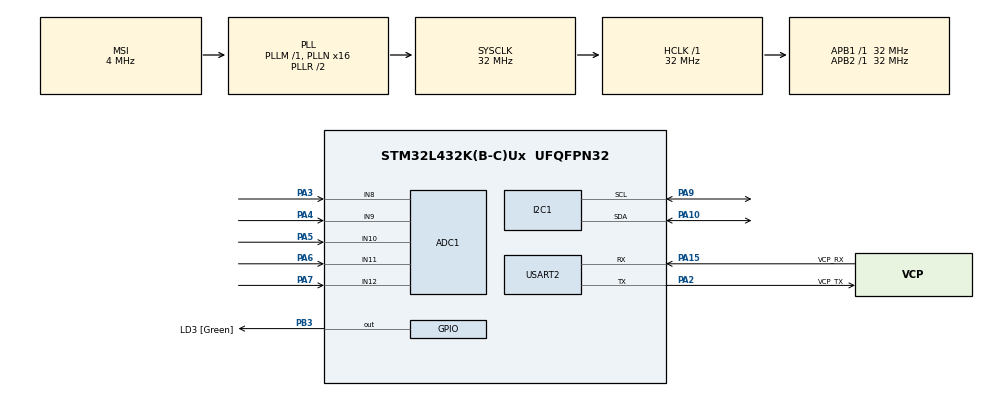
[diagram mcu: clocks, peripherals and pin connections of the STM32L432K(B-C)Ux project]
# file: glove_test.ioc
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ADC1.Channel-0\#ChannelRegularConversion=ADC_CHANNEL_8
ADC1.Channel-1\#ChannelRegularConversion=ADC_CHANNEL_9
ADC1.Channel-2\#ChannelRegularConversion=ADC_CHANNEL_10
ADC1.Channel-3\#ChannelRegularConversion=ADC_CHANNEL_11
ADC1.Channel-4\#ChannelRegularConversion=ADC_CHANNEL_12
ADC1.ClockPrescaler=ADC_CLOCK_SYNC_PCLK_DIV4
ADC1.ContinuousConvMode=ENABLE
ADC1.DMAContinuousRequests=ENABLE
ADC1.NbrOfConversion=5
ADC1.NbrOfConversionFlag=1
ADC1.OffsetNumber-0\#ChannelRegularConversion=ADC_OFFSET_NONE
ADC1.OffsetNumber-1\#ChannelRegularConversion=ADC_OFFSET_NONE
ADC1.OffsetNumber-2\#ChannelRegularConversion=ADC_OFFSET_NONE
ADC1.OffsetNumber-3\#ChannelRegularConversion=ADC_OFFSET_NONE
ADC1.OffsetNumber-4\#ChannelRegularConversion=ADC_OFFSET_NONE
ADC1.Rank-0\#ChannelRegularConversion=1
ADC1.Rank-1\#ChannelRegularConversion=2
ADC1.Rank-2\#ChannelRegularConversion=3
ADC1.Rank-3\#ChannelRegularConversion=4
ADC1.Rank-4\#ChannelRegularConversion=5
ADC1.SamplingTime-0\#ChannelRegularConversion=ADC_SAMPLETIME_2CYCLES_5
ADC1.SamplingTime-1\#ChannelRegularConversion=ADC_SAMPLETIME_2CYCLES_5
ADC1.SamplingTime-2\#ChannelRegularConversion=ADC_SAMPLETIME_2CYCLES_5
ADC1.SamplingTime-3\#ChannelRegularConversion=ADC_SAMPLETIME_2CYCLES_5
ADC1.SamplingTime-4\#ChannelRegularConversion=ADC_SAMPLETIME_2CYCLES_5
ADC1.master=1
Dma.ADC1.0.Direction=DMA_PERIPH_TO_MEMORY
Dma.ADC1.0.Instance=DMA1_Channel1
Dma.ADC1.0.MemDataAlignment=DMA_MDATAALIGN_HALFWORD
Dma.ADC1.0.MemInc=DMA_MINC_ENABLE
Dma.ADC1.0.Mode=DMA_CIRCULAR
Dma.ADC1.0.PeriphDataAlignment=DMA_PDATAALIGN_HALFWORD
Dma.ADC1.0.PeriphInc=DMA_PINC_DISABLE
Dma.ADC1.0.Priority=DMA_PRIORITY_LOW
Dma.Request0=ADC1
I2C1.Timing=0x00707CBB
Mcu.Family=STM32L4
Mcu.Name=STM32L432K(B-C)Ux
Mcu.Package=UFQFPN32
NVIC.DMA1_Channel1_IRQn=true\:0\:0\:false\:false\:true\:false\:true
NVIC.PriorityGroup=NVIC_PRIORITYGROUP_4
PA0.GPIO_Label=MCO [High speed clock in]
PA0.Mode=HSE-External-Clock-Source-for-LittleOrca
PA0.Signal=RCC_CK_IN
PA10.Mode=I2C
PA10.Signal=I2C1_SDA
PA13\ (JTMS-SWDIO).GPIO_Label=SWDIO
PA13\ (JTMS-SWDIO).Mode=Serial_Wire
PA13\ (JTMS-SWDIO).Signal=SYS_JTMS-SWDIO
PA14\ (JTCK-SWCLK).GPIO_Label=SWCLK
PA14\ (JTCK-SWCLK).Mode=Serial_Wire
PA14\ (JTCK-SWCLK).Signal=SYS_JTCK-SWCLK
PA15\ (JTDI).GPIO_Label=VCP_RX
PA15\ (JTDI).Mode=Asynchronous
PA15\ (JTDI).Signal=USART2_RX
PA2.GPIO_Label=VCP_TX
PA2.Mode=Asynchronous
PA2.Signal=USART2_TX
PA3.Signal=ADCx_IN8
PA4.Signal=ADCx_IN9
PA5.Signal=ADCx_IN10
PA6.Signal=ADCx_IN11
PA7.Signal=ADCx_IN12
PA9.Mode=I2C
PA9.Signal=I2C1_SCL
PB3\ (JTDO-TRACESWO).GPIO_Label=LD3 [Green]
PB3\ (JTDO-TRACESWO).Signal=GPIO_Output
PC14-OSC32_IN\ (PC14).Mode=LSE-External-Oscillator
PC14-OSC32_IN\ (PC14).Signal=RCC_OSC32_IN
PC15-OSC32_OUT\ (PC15).Mode=LSE-External-Oscillator
PC15-OSC32_OUT\ (PC15).Signal=RCC_OSC32_OUT
ProjectManager.HeapSize=0x200
ProjectManager.StackSize=0x400
ProjectManager.TargetToolchain=TrueSTUDIO
RCC.ADCFreq_Value=32000000
RCC.AHBFreq_Value=32000000
RCC.APB1Freq_Value=32000000
RCC.APB1TimFreq_Value=32000000
RCC.APB2Freq_Value=32000000
RCC.APB2TimFreq_Value=32000000
RCC.CortexFreq_Value=32000000
RCC.HCLKFreq_Value=32000000
RCC.HSE_VALUE=8000000
RCC.HSI16_VALUE=16000000
RCC.HSI48_VALUE=48000000
RCC.HSI_VALUE=16000000
RCC.MSI_VALUE=4000000
RCC.PLLMUL=RCC_PLLMUL_4
RCC.PLLN=16
RCC.PLLSAI1N=16
RCC.SYSCLKFreq_VALUE=32000000
RCC.SYSCLKSource=RCC_SYSCLKSOURCE_PLLCLK
RCC.USBFreq_Value=32000000
RCC.VCOOutputFreq_Value=64000000
SH.ADCx_IN10.0=ADC1_IN10,IN10-Single-Ended
SH.ADCx_IN11.0=ADC1_IN11,IN11-Single-Ended
SH.ADCx_IN12.0=ADC1_IN12,IN12-Single-Ended
SH.ADCx_IN8.0=ADC1_IN8,IN8-Single-Ended
SH.ADCx_IN9.0=ADC1_IN9,IN9-Single-Ended
USART2.VirtualMode-Asynchronous=VM_ASYNC
board=NUCLEO-L432KC

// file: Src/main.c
#include "main.h"
#include <stdio.h>
#include <string.h>

ADC_HandleTypeDef hadc1;
DMA_HandleTypeDef hdma_adc1;
I2C_HandleTypeDef hi2c1;
UART_HandleTypeDef huart2;

/* USER CODE BEGIN PV */
uint16_t adcBuffer[5];
uint16_t angle[5];
char adc_value[20] = { 0 };

/* USER CODE END PV */

void SystemClock_Config(void);
static void MX_GPIO_Init(void);
static void MX_DMA_Init(void);
static void MX_ADC1_Init(void);
static void MX_USART2_UART_Init(void);
static void MX_I2C1_Init(void);

void ScreenSend(uint8_t * pData) {
	int length = strlen((char*) pData);	//Calculate string length
	HAL_I2C_Master_Transmit(&hi2c1, 0x72 << 1, pData, length, 10);//Address 0x72
}

long map(long x, long in_min, long in_max, long out_min, long out_max) {
	return (x - in_min) * (out_max - out_min) / (in_max - in_min) + out_min;
}

void thumbFinger(uint16_t angle);
void indexFinger(uint16_t angle);
void middleFinger(uint16_t angle);
void ringFinger(uint16_t angle);
void littleFinger(uint16_t angle);

void thumbFinger(uint16_t angle) {
	if (angle >= 30 && angle <= 40) {
		printf("Finger Bend at 35.\r\n");
		ScreenSend((uint8_t *) "|-I need water");
	}

	else if (angle >= 85 && angle <= 95) {
		printf("Finger Bend at 90.\r\n");
		ScreenSend((uint8_t *) "|-I need food");
	}

	else if (angle >= 105 && angle <= 115) {
		printf("Finger Bend at 120.\r\n");
		ScreenSend((uint8_t *) "|-I need medicine");
	}
	HAL_Delay(100);
}

void indexFinger(uint16_t angle) {
	if (angle >= 30 && angle <= 40) {
		printf("Finger Bend at 35.\r\n");
		ScreenSend((uint8_t *) "|-Hello, I'm Aman!");
	}

	else if (angle >= 85 && angle <= 95) {
		printf("Finger Bend at 90.\r\n");
		ScreenSend((uint8_t *) "|-I'm good");
	}

	else if (angle >= 105 && angle <= 115) {
		printf("Finger Bend at 120.\r\n");
		ScreenSend((uint8_t *) "|-How are you?");
	}
	HAL_Delay(100);
}

void middleFinger(uint16_t angle) {
	if (angle >= 30 && angle <= 40) {
		printf("Finger Bend at 35.\r\n");
		ScreenSend((uint8_t *) "|-I need wheelchair");
	}

	else if (angle >= 85 && angle <= 95) {
		printf("Finger Bend at 90.\r\n");
		ScreenSend((uint8_t *) "|-I'm tired");
	}

	else if (angle >= 105 && angle <= 115) {
		printf("Finger Bend at 120.\r\n");
		ScreenSend((uint8_t *) "|-I'm sleepy");
	}
	HAL_Delay(100);
}

void ringFinger(uint16_t angle) {
	if (angle >= 30 && angle <= 40) {
		printf("Finger Bend at 35.\r\n");
		ScreenSend((uint8_t *) "|-Where's my phone?");
	}

	else if (angle >= 85 && angle <= 95) {
		printf("Finger Bend at 90.\r\n");
		ScreenSend((uint8_t *) "|-Call on this number.");
	}

	else if (angle >= 105 && angle <= 115) {
		printf("Finger Bend at 120.\r\n");
		ScreenSend((uint8_t *) "|-Tell my address.");
	}
	HAL_Delay(100);
}

void littleFinger(uint16_t angle) {
	if (angle >= 30 && angle <= 40) {
		printf("Finger Bend at 35.\r\n");
		ScreenSend((uint8_t *) "|-Thank you!");
	}

	else if (angle >= 85 && angle <= 95) {
		printf("Finger Bend at 90.\r\n");
		ScreenSend((uint8_t *) "|-Nice to meet you.");
	}

	else if (angle >= 105 && angle <= 115) {
		printf("Finger Bend at 120.\r\n");
		ScreenSend((uint8_t *) "|-Goodbye");
	}
	HAL_Delay(100);
}

int main(void) {

	/* MCU Configuration--------------------------------------------------------*/
	/* Reset of all peripherals, Initializes the Flash interface and the Systick. */
	HAL_Init();

	/* Configure the system clock */
	SystemClock_Config();

	/* Initialize all configured peripherals */
	MX_GPIO_Init();
	MX_DMA_Init();
	MX_ADC1_Init();
	MX_USART2_UART_Init();
	MX_I2C1_Init();

	HAL_ADC_Start_DMA(&hadc1, (uint32_t*) adcBuffer, 5); // Start ADC in DMA

	while (HAL_I2C_IsDeviceReady(&hi2c1, 0x72 << 1, 2, 10) != HAL_OK) {
	}   		//Wait for LCD

#ifdef SETBACKLIGHT
	uint8_t setupData[] = {'|', 128 + 15, '|', 158 + 15, '|', 188 + 20}; //set backlight (R, G, B)
	ScreenSend(setupData);
#endif

	ScreenSend((uint8_t *) "|-Smart Glove");	//Boot message
	HAL_Delay(500);

	/* Infinite loop */
	while (1) {
		printf("ADC > 1: %d  2: %d  3: %d  4: %d  5: %d \r\n", adcBuffer[0],
				adcBuffer[1], adcBuffer[2], adcBuffer[3], adcBuffer[4]);

		angle[0] = map(adcBuffer[0], 2840, 3670, 0, 180);
		angle[1] = map(adcBuffer[1], 2900, 3670, 0, 180);
		angle[2] = map(adcBuffer[2], 2860, 3670, 0, 180);
		angle[3] = map(adcBuffer[3], 2900, 3670, 0, 180);
		angle[4] = map(adcBuffer[4], 3000, 3670, 0, 180);

		printf("Angle > 1: %d  2: %d  3: %d  4: %d  5: %d \r\n\n", angle[0],
				angle[1], angle[2], angle[3], angle[4]);

		thumbFinger(angle[0]);
		indexFinger(angle[1]);
		middleFinger(angle[2]);
		ringFinger(angle[3]);
		littleFinger(angle[4]);

	}
	/* USER CODE END 3 */
}

void SystemClock_Config(void) {
	RCC_OscInitTypeDef RCC_OscInitStruct = { 0 };
	RCC_ClkInitTypeDef RCC_ClkInitStruct = { 0 };
	RCC_PeriphCLKInitTypeDef PeriphClkInit = { 0 };

	/** Configure LSE Drive Capability
	 */
	HAL_PWR_EnableBkUpAccess();
	__HAL_RCC_LSEDRIVE_CONFIG(RCC_LSEDRIVE_LOW);
	/** Initializes the CPU, AHB and APB busses clocks
	 */
	RCC_OscInitStruct.OscillatorType = RCC_OSCILLATORTYPE_LSE
			| RCC_OSCILLATORTYPE_MSI;
	RCC_OscInitStruct.LSEState = RCC_LSE_ON;
	RCC_OscInitStruct.MSIState = RCC_MSI_ON;
	RCC_OscInitStruct.MSICalibrationValue = 0;
	RCC_OscInitStruct.MSIClockRange = RCC_MSIRANGE_6;
	RCC_OscInitStruct.PLL.PLLState = RCC_PLL_ON;
	RCC_OscInitStruct.PLL.PLLSource = RCC_PLLSOURCE_MSI;
	RCC_OscInitStruct.PLL.PLLM = 1;
	RCC_OscInitStruct.PLL.PLLN = 16;
	RCC_OscInitStruct.PLL.PLLP = RCC_PLLP_DIV7;
	RCC_OscInitStruct.PLL.PLLQ = RCC_PLLQ_DIV2;
	RCC_OscInitStruct.PLL.PLLR = RCC_PLLR_DIV2;
	if (HAL_RCC_OscConfig(&RCC_OscInitStruct) != HAL_OK) {
		Error_Handler();
	}
	/** Initializes the CPU, AHB and APB busses clocks
	 */
	RCC_ClkInitStruct.ClockType = RCC_CLOCKTYPE_HCLK | RCC_CLOCKTYPE_SYSCLK
			| RCC_CLOCKTYPE_PCLK1 | RCC_CLOCKTYPE_PCLK2;
	RCC_ClkInitStruct.SYSCLKSource = RCC_SYSCLKSOURCE_PLLCLK;
	RCC_ClkInitStruct.AHBCLKDivider = RCC_SYSCLK_DIV1;
	RCC_ClkInitStruct.APB1CLKDivider = RCC_HCLK_DIV1;
	RCC_ClkInitStruct.APB2CLKDivider = RCC_HCLK_DIV1;

	if (HAL_RCC_ClockConfig(&RCC_ClkInitStruct, FLASH_LATENCY_1) != HAL_OK) {
		Error_Handler();
	}
	PeriphClkInit.PeriphClockSelection = RCC_PERIPHCLK_USART2
			| RCC_PERIPHCLK_I2C1 | RCC_PERIPHCLK_ADC;
	PeriphClkInit.Usart2ClockSelection = RCC_USART2CLKSOURCE_PCLK1;
	PeriphClkInit.I2c1ClockSelection = RCC_I2C1CLKSOURCE_PCLK1;
	PeriphClkInit.AdcClockSelection = RCC_ADCCLKSOURCE_PLLSAI1;
	PeriphClkInit.PLLSAI1.PLLSAI1Source = RCC_PLLSOURCE_MSI;
	PeriphClkInit.PLLSAI1.PLLSAI1M = 1;
	PeriphClkInit.PLLSAI1.PLLSAI1N = 16;
	PeriphClkInit.PLLSAI1.PLLSAI1P = RCC_PLLP_DIV7;
	PeriphClkInit.PLLSAI1.PLLSAI1Q = RCC_PLLQ_DIV2;
	PeriphClkInit.PLLSAI1.PLLSAI1R = RCC_PLLR_DIV2;
	PeriphClkInit.PLLSAI1.PLLSAI1ClockOut = RCC_PLLSAI1_ADC1CLK;
	if (HAL_RCCEx_PeriphCLKConfig(&PeriphClkInit) != HAL_OK) {
		Error_Handler();
	}
	/** Configure the main internal regulator output voltage
	 */
	if (HAL_PWREx_ControlVoltageScaling(PWR_REGULATOR_VOLTAGE_SCALE1)
			!= HAL_OK) {
		Error_Handler();
	}
	/** Enable MSI Auto calibration
	 */
	HAL_RCCEx_EnableMSIPLLMode();
}

static void MX_ADC1_Init(void) {

	ADC_ChannelConfTypeDef sConfig = { 0 };

	/** Common config
	 */
	hadc1.Instance = ADC1;
	hadc1.Init.ClockPrescaler = ADC_CLOCK_SYNC_PCLK_DIV4;
	hadc1.Init.Resolution = ADC_RESOLUTION_12B;
	hadc1.Init.DataAlign = ADC_DATAALIGN_RIGHT;
	hadc1.Init.ScanConvMode = ADC_SCAN_ENABLE;
	hadc1.Init.EOCSelection = ADC_EOC_SINGLE_CONV;
	hadc1.Init.LowPowerAutoWait = DISABLE;
	hadc1.Init.ContinuousConvMode = ENABLE;
	hadc1.Init.NbrOfConversion = 5;
	hadc1.Init.DiscontinuousConvMode = DISABLE;
	hadc1.Init.ExternalTrigConv = ADC_SOFTWARE_START;
	hadc1.Init.ExternalTrigConvEdge = ADC_EXTERNALTRIGCONVEDGE_NONE;
	hadc1.Init.DMAContinuousRequests = ENABLE;
	hadc1.Init.Overrun = ADC_OVR_DATA_PRESERVED;
	hadc1.Init.OversamplingMode = DISABLE;
	if (HAL_ADC_Init(&hadc1) != HAL_OK) {
		Error_Handler();
	}
	/** Configure Regular Channel
	 */
	sConfig.Channel = ADC_CHANNEL_8;
	sConfig.Rank = ADC_REGULAR_RANK_1;
	sConfig.SamplingTime = ADC_SAMPLETIME_2CYCLES_5;
	sConfig.SingleDiff = ADC_SINGLE_ENDED;
	sConfig.OffsetNumber = ADC_OFFSET_NONE;
	sConfig.Offset = 0;
	if (HAL_ADC_ConfigChannel(&hadc1, &sConfig) != HAL_OK) {
		Error_Handler();
	}
	/** Configure Regular Channel
	 */
	sConfig.Channel = ADC_CHANNEL_9;
	sConfig.Rank = ADC_REGULAR_RANK_2;
	if (HAL_ADC_ConfigChannel(&hadc1, &sConfig) != HAL_OK) {
		Error_Handler();
	}
	/** Configure Regular Channel
	 */
	sConfig.Channel = ADC_CHANNEL_10;
	sConfig.Rank = ADC_REGULAR_RANK_3;
	if (HAL_ADC_ConfigChannel(&hadc1, &sConfig) != HAL_OK) {
		Error_Handler();
	}
	/** Configure Regular Channel
	 */
	sConfig.Channel = ADC_CHANNEL_11;
	sConfig.Rank = ADC_REGULAR_RANK_4;
	if (HAL_ADC_ConfigChannel(&hadc1, &sConfig) != HAL_OK) {
		Error_Handler();
	}
	/** Configure Regular Channel
	 */
	sConfig.Channel = ADC_CHANNEL_12;
	sConfig.Rank = ADC_REGULAR_RANK_5;
	if (HAL_ADC_ConfigChannel(&hadc1, &sConfig) != HAL_OK) {
		Error_Handler();
	}

}

static void MX_I2C1_Init(void) {

	hi2c1.Instance = I2C1;
	hi2c1.Init.Timing = 0x00707CBB;
	hi2c1.Init.OwnAddress1 = 0;
	hi2c1.Init.AddressingMode = I2C_ADDRESSINGMODE_7BIT;
	hi2c1.Init.DualAddressMode = I2C_DUALADDRESS_DISABLE;
	hi2c1.Init.OwnAddress2 = 0;
	hi2c1.Init.OwnAddress2Masks = I2C_OA2_NOMASK;
	hi2c1.Init.GeneralCallMode = I2C_GENERALCALL_DISABLE;
	hi2c1.Init.NoStretchMode = I2C_NOSTRETCH_DISABLE;
	if (HAL_I2C_Init(&hi2c1) != HAL_OK) {
		Error_Handler();
	}
	/** Configure Analogue filter
	 */
	if (HAL_I2CEx_ConfigAnalogFilter(&hi2c1, I2C_ANALOGFILTER_ENABLE)
			!= HAL_OK) {
		Error_Handler();
	}
	/** Configure Digital filter
	 */
	if (HAL_I2CEx_ConfigDigitalFilter(&hi2c1, 0) != HAL_OK) {
		Error_Handler();
	}

}

static void MX_USART2_UART_Init(void) {

	huart2.Instance = USART2;
	huart2.Init.BaudRate = 115200;
	huart2.Init.WordLength = UART_WORDLENGTH_8B;
	huart2.Init.StopBits = UART_STOPBITS_1;
	huart2.Init.Parity = UART_PARITY_NONE;
	huart2.Init.Mode = UART_MODE_TX_RX;
	huart2.Init.HwFlowCtl = UART_HWCONTROL_NONE;
	huart2.Init.OverSampling = UART_OVERSAMPLING_16;
	huart2.Init.OneBitSampling = UART_ONE_BIT_SAMPLE_DISABLE;
	huart2.AdvancedInit.AdvFeatureInit = UART_ADVFEATURE_NO_INIT;
	if (HAL_UART_Init(&huart2) != HAL_OK) {
		Error_Handler();
	}

}

static void MX_DMA_Init(void) {
	/* DMA controller clock enable */
	__HAL_RCC_DMA1_CLK_ENABLE()
	;

	/* DMA interrupt init */
	/* DMA1_Channel1_IRQn interrupt configuration */
	HAL_NVIC_SetPriority(DMA1_Channel1_IRQn, 0, 0);
	HAL_NVIC_EnableIRQ(DMA1_Channel1_IRQn);

}

static void MX_GPIO_Init(void) {
	GPIO_InitTypeDef GPIO_InitStruct = { 0 };

	/* GPIO Ports Clock Enable */
	__HAL_RCC_GPIOC_CLK_ENABLE()
	;
	__HAL_RCC_GPIOA_CLK_ENABLE()
	;
	__HAL_RCC_GPIOB_CLK_ENABLE()
	;

	/*Configure GPIO pin Output Level */
	HAL_GPIO_WritePin(LD3_GPIO_Port, LD3_Pin, GPIO_PIN_RESET);

	/*Configure GPIO pin : LD3_Pin */
	GPIO_InitStruct.Pin = LD3_Pin;
	GPIO_InitStruct.Mode = GPIO_MODE_OUTPUT_PP;
	GPIO_InitStruct.Pull = GPIO_NOPULL;
	GPIO_InitStruct.Speed = GPIO_SPEED_FREQ_LOW;
	HAL_GPIO_Init(LD3_GPIO_Port, &GPIO_InitStruct);

}

void Error_Handler(void) {
}

/************************ (C) COPYRIGHT STMicroelectronics *****END OF FILE****/
